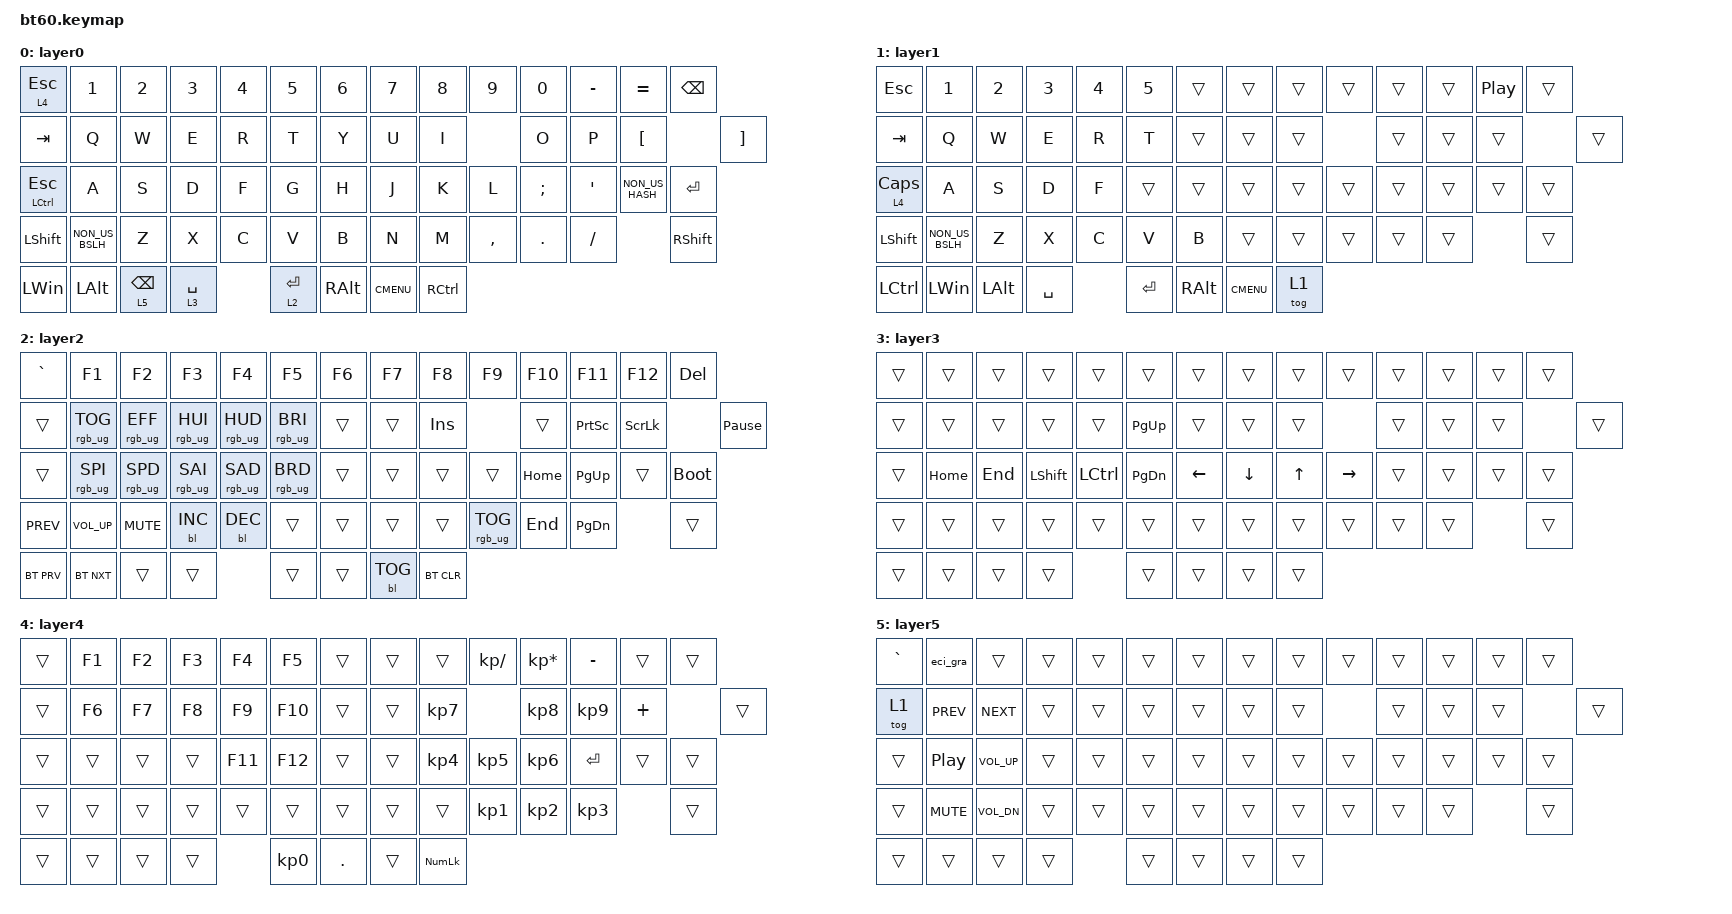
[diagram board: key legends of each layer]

  /*
  * Copyright (c) 2020 The ZMK Contributors
  *
  * SPDX-License-Identifier: MIT
  */

  #include <behaviors.dtsi>
  #include <dt-bindings/zmk/keys.h>
  #include <dt-bindings/zmk/bt.h>
  #include <dt-bindings/zmk/ext_power.h>

  / {
    keymap {
      compatible = "zmk,keymap";
      layer0 {
              bindings = <
              &lt 4 ESC &kp N1 &kp N2 &kp N3 &kp N4 &kp N5 &kp N6 &kp N7 &kp N8 &kp N9 &kp N0 &kp MINUS &kp EQUAL &kp BSPC
              &kp TAB &kp Q &kp W &kp E &kp R &kp T &kp Y &kp U &kp I &kp O &kp P &kp LBKT &kp RBKT
              &mt LCTRL ESCAPE &kp A &kp S &kp D &kp F &kp G &kp H &kp J &kp K &kp L &kp SEMI &kp SQT &kp NON_US_HASH &kp RET
              &kp LSHFT &kp NON_US_BSLH &kp Z &kp X &kp C &kp V &kp B &kp N &kp M &kp COMMA &kp DOT &kp FSLH &kp RSHFT
              &kp LEFT_WIN &kp LEFT_ALT &lt 5 BACKSPACE &lt 3 SPACE &lt 2 ENTER &kp RALT &kp K_CMENU &kp RCTRL
              >;
            };
      layer1 {
              bindings = <
              &kp ESC &kp N1 &kp N2 &kp N3 &kp N4 &kp N5 &trans &trans &trans &trans &trans &trans &kp C_PLAY_PAUSE &trans
              &kp TAB &kp Q &kp W &kp E &kp R &kp T &trans &trans &trans &trans &trans &trans &trans
              &lt 4 CAPSLOCK &kp A &kp S &kp D &kp F &trans &trans &trans &trans &trans &trans &trans &trans &trans
              &kp LSHFT &kp NON_US_BSLH &kp Z &kp X &kp C &kp V &kp B &trans &trans &trans &trans &trans &trans
              &kp LCTRL &kp LEFT_WIN &kp LEFT_ALT &kp SPACE &kp ENTER &kp RALT &kp K_CMENU &tog 1
              >;
            };
      layer2 {
              bindings = <
              &kp GRAVE &kp F1 &kp F2 &kp F3 &kp F4 &kp F5 &kp F6 &kp F7 &kp F8 &kp F9 &kp F10 &kp F11 &kp F12 &kp DEL
              &trans &rgb_ug RGB_TOG &rgb_ug RGB_EFF &rgb_ug RGB_HUI &rgb_ug RGB_HUD &rgb_ug RGB_BRI &trans &trans &kp INS &trans &kp PSCRN &kp SLCK &kp PAUSE_BREAK
              &trans &rgb_ug RGB_SPI &rgb_ug RGB_SPD &rgb_ug RGB_SAI &rgb_ug RGB_SAD &rgb_ug RGB_BRD &trans &trans &trans &trans &kp HOME &kp PG_UP &trans &bootloader
              &kp C_PREV &kp C_VOL_UP &kp C_MUTE &bl BL_INC &bl BL_DEC &trans &trans &trans &trans &rgb_ug RGB_TOG &kp END &kp PG_DN &trans
              &bt BT_PRV &bt BT_NXT &trans &trans &trans &trans &bl BL_TOG &bt BT_CLR
              >;
            };
      layer3 {
              bindings = <
              &trans &trans &trans &trans &trans &trans &trans &trans &trans &trans &trans &trans &trans &trans &trans &trans &trans &trans &trans &kp PAGE_UP &trans &trans &trans &trans &trans &trans &trans &trans &kp HOME &kp END &kp LSHIFT &kp LCTRL &kp PAGE_DOWN &kp LEFT &kp DOWN &kp UP &kp RIGHT &trans &trans &trans &trans &trans &trans &trans &trans &trans &trans &trans &trans &trans &trans &trans &trans &trans &trans &trans &trans &trans &trans &trans &trans &trans
              >;
            };
      layer4 {
              bindings = <
              &trans &kp F1 &kp F2 &kp F3 &kp F4 &kp F5 &trans &trans &trans &kp KP_DIVIDE &kp KP_MULTIPLY &kp MINUS &trans &trans
              &trans &kp F6 &kp F7 &kp F8 &kp F9 &kp F10 &trans &trans &kp KP_NUMBER_7 &kp KP_NUMBER_8 &kp KP_NUMBER_9 &kp PLUS &trans
              &trans &trans &trans &trans &kp F11 &kp F12 &trans &trans &kp KP_NUMBER_4 &kp KP_NUMBER_5 &kp KP_NUMBER_6 &kp ENTER &trans &trans
              &trans &trans &trans &trans &trans &trans &trans &trans &trans &kp KP_NUMBER_1 &kp KP_NUMBER_2 &kp KP_NUMBER_3 &trans
              &trans &trans &trans &trans &kp KP_NUMBER_0 &kp DOT &trans &kp KP_NUMLOCK
              >;
            };
      layer5 {
              bindings = <
              &kp GRAVE &eci_gra &trans &trans &trans &trans &trans &trans &trans &trans &trans &trans &trans &trans
              &tog 1 &kp C_PREV &kp C_NEXT &trans &trans &trans &trans &trans &trans &trans &trans &trans &trans
              &trans &kp C_PLAY_PAUSE &kp C_VOL_UP &trans &trans &trans &trans &trans &trans &trans &trans &trans &trans &trans
              &trans &kp C_MUTE &kp C_VOL_DN &trans &trans &trans &trans &trans &trans &trans &trans &trans &trans
              &trans &trans &trans &trans &trans &trans &trans &trans
              >;
            };
        };
  };
